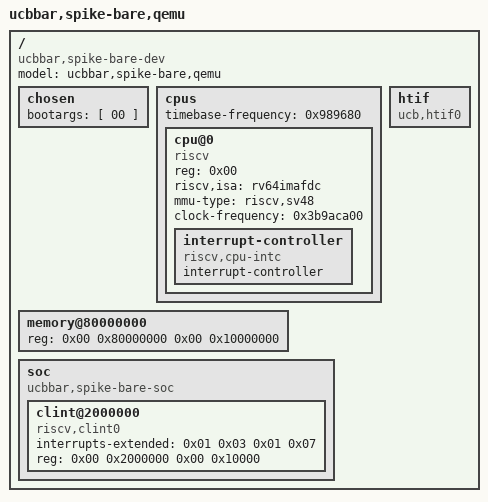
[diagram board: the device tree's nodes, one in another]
/dts-v1/;

/ {
	#address-cells = < 0x02 >;
	#size-cells = < 0x02 >;
	compatible = "ucbbar,spike-bare-dev";
	model = "ucbbar,spike-bare,qemu";

	chosen {
		bootargs = [ 00 ];
	};

	cpus {
		#address-cells = < 0x01 >;
		#size-cells = < 0x00 >;
		timebase-frequency = < 0x989680 >;

		cpu@0 {
			device_type = "cpu";
			reg = < 0x00 >;
			status = "okay";
			compatible = "riscv";
			riscv,isa = "rv64imafdc";
			mmu-type = "riscv,sv48";
			clock-frequency = < 0x3b9aca00 >;

			interrupt-controller {
				#interrupt-cells = < 0x01 >;
				interrupt-controller;
				compatible = "riscv,cpu-intc";
				linux,phandle = < 0x01 >;
				phandle = < 0x01 >;
			};
		};
	};

	memory@80000000 {
		device_type = "memory";
		reg = < 0x00 0x80000000 0x00 0x10000000 >;
	};

	soc {
		#address-cells = < 0x02 >;
		#size-cells = < 0x02 >;
		compatible = "ucbbar,spike-bare-soc";
		ranges;

		clint@2000000 {
			interrupts-extended = < 0x01 0x03 0x01 0x07 >;
			reg = < 0x00 0x2000000 0x00 0x10000 >;
			compatible = "riscv,clint0";
		};
	};

	htif {
		compatible = "ucb,htif0";
	};
};
